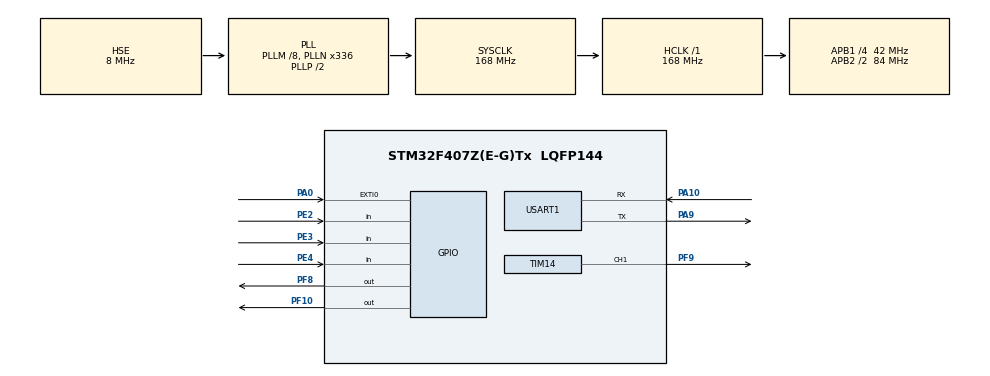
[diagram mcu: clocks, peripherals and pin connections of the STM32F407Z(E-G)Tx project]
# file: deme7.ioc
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Mcu.Family=STM32F4
Mcu.Name=STM32F407Z(E-G)Tx
Mcu.Package=LQFP144
NVIC.EXTI0_IRQn=true\:2\:3\:true\:false\:true\:true\:true
NVIC.PriorityGroup=NVIC_PRIORITYGROUP_2
NVIC.TIM3_IRQn=true\:2\:2\:true\:false\:true\:true\:true
NVIC.TIM7_IRQn=true\:1\:2\:true\:false\:true\:true\:true
NVIC.USART1_IRQn=true\:3\:3\:true\:false\:true\:true\:true
PA0-WKUP.GPIO_ModeDefaultEXTI=GPIO_MODE_IT_RISING
PA0-WKUP.GPIO_PuPd=GPIO_PULLDOWN
PA0-WKUP.Signal=GPXTI0
PA10.GPIO_Speed=GPIO_SPEED_FREQ_HIGH
PA10.Mode=Asynchronous
PA10.Signal=USART1_RX
PA9.GPIO_ModeDefaultPP=GPIO_MODE_AF_PP
PA9.Mode=Asynchronous
PA9.Signal=USART1_TX
PE2.GPIO_PuPd=GPIO_PULLUP
PE2.Signal=GPIO_Input
PE3.GPIO_PuPd=GPIO_PULLUP
PE3.Signal=GPIO_Input
PE4.GPIO_PuPd=GPIO_PULLUP
PE4.Signal=GPIO_Input
PF10.GPIO_ModeDefaultOutputPP=GPIO_MODE_OUTPUT_PP
PF10.GPIO_PuPd=GPIO_PULLUP
PF10.GPIO_Speed=GPIO_SPEED_FREQ_HIGH
PF10.PinState=GPIO_PIN_SET
PF10.Signal=GPIO_Output
PF8.GPIO_ModeDefaultOutputPP=GPIO_MODE_OUTPUT_PP
PF8.GPIO_PuPd=GPIO_PULLDOWN
PF8.GPIO_Speed=GPIO_SPEED_FREQ_HIGH
PF8.PinState=GPIO_PIN_SET
PF8.Signal=GPIO_Output
PF9.GPIO_ModeDefaultPP=GPIO_MODE_AF_PP
PF9.GPIO_PuPd=GPIO_PULLUP
PF9.GPIO_Speed=GPIO_SPEED_FREQ_HIGH
PF9.Signal=S_TIM14_CH1
PH0-OSC_IN.Mode=HSE-External-Oscillator
PH0-OSC_IN.Signal=RCC_OSC_IN
PH1-OSC_OUT.Mode=HSE-External-Oscillator
PH1-OSC_OUT.Signal=RCC_OSC_OUT
ProjectManager.HeapSize=0x200
ProjectManager.StackSize=0x400
ProjectManager.TargetToolchain=MDK-ARM V5.27
RCC.48MHZClocksFreq_Value=84000000
RCC.AHBFreq_Value=168000000
RCC.APB1CLKDivider=RCC_HCLK_DIV4
RCC.APB1Freq_Value=42000000
RCC.APB1TimFreq_Value=84000000
RCC.APB2CLKDivider=RCC_HCLK_DIV2
RCC.APB2Freq_Value=84000000
RCC.APB2TimFreq_Value=168000000
RCC.CortexFreq_Value=168000000
RCC.HCLKFreq_Value=168000000
RCC.HSE_VALUE=8000000
RCC.HSI_VALUE=16000000
RCC.LSE_VALUE=32768
RCC.PLLM=8
RCC.PLLN=336
RCC.PLLSourceVirtual=RCC_PLLSOURCE_HSE
RCC.SYSCLKFreq_VALUE=168000000
RCC.SYSCLKSource=RCC_SYSCLKSOURCE_PLLCLK
RCC.VCOOutputFreq_Value=336000000
SH.S_TIM14_CH1.0=TIM14_CH1,PWM Generation1 CH1
TIM14.AutoReloadPreload=TIM_AUTORELOAD_PRELOAD_ENABLE
TIM14.Channel=TIM_CHANNEL_1
TIM14.Period=499
TIM14.Prescaler=83
TIM3.AutoReloadPreload=TIM_AUTORELOAD_PRELOAD_ENABLE
TIM3.Period=1000
TIM3.Prescaler=8399
TIM7.AutoReloadPreload=TIM_AUTORELOAD_PRELOAD_ENABLE
TIM7.Period=1000
TIM7.Prescaler=8499
USART1.VirtualMode=VM_ASYNC
VP_TIM14_VS_ClockSourceINT.Mode=Enable_Timer
VP_TIM3_VS_ClockSourceINT.Mode=Internal
VP_TIM7_VS_ClockSourceINT.Mode=Enable_Timer
board=custom

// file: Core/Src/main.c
/* USER CODE BEGIN Header */
/**
  ******************************************************************************
  * @file           : main.c
  * @brief          : Main program body
  ******************************************************************************
  * @attention
  *
  * <h2><center>&copy; Copyright (c) 2021 STMicroelectronics.
  * All rights reserved.</center></h2>
  *
  * This software component is licensed by ST under BSD 3-Clause license,
  * the "License"; You may not use this file except in compliance with the
  * License. You may obtain a copy of the License at:
  *                        opensource.org/licenses/BSD-3-Clause
  *
  ******************************************************************************
  */
/* USER CODE END Header */
#include "main.h"
#include "tim.h"
#include "usart.h"
#include "gpio.h"

void SystemClock_Config(void);

int main(void)
{
  /* USER CODE BEGIN 1 */
	unsigned char data_buf[1];
	data_buf[0] = 0xff;
  /* USER CODE END 1 */

  /* MCU Configuration--------------------------------------------------------*/

  /* Reset of all peripherals, Initializes the Flash interface and the Systick. */
  HAL_Init();

  /* Configure the system clock */
  SystemClock_Config();

  /* Initialize all configured peripherals */
  MX_GPIO_Init();
  MX_TIM7_Init();
  MX_USART1_UART_Init();
  MX_TIM14_Init();
  MX_TIM3_Init();
  /* USER CODE BEGIN 2 */
	LED1(0);
	BEEP(0);
	Beep(0);

  /* USER CODE END 2 */

  /* Infinite loop */
  while (1)
  {

    /* USER CODE BEGIN 3 */
	  //printf("%d\n\r",0XFF);
	  if(key_state){
		  LED1(1);
	  }else{
		  LED1(0);
	  }
	  data_buf[0] = Key_Scan();
	  //HAL_UART_Transmit(&huart1, data_buf, 1, 100);
	  HAL_Delay(50);
  }
  /* USER CODE END 3 */
}

void SystemClock_Config(void)
{
  RCC_OscInitTypeDef RCC_OscInitStruct = {0};
  RCC_ClkInitTypeDef RCC_ClkInitStruct = {0};

  /** Configure the main internal regulator output voltage
  */
  __HAL_RCC_PWR_CLK_ENABLE();
  __HAL_PWR_VOLTAGESCALING_CONFIG(PWR_REGULATOR_VOLTAGE_SCALE1);
  /** Initializes the RCC Oscillators according to the specified parameters
  * in the RCC_OscInitTypeDef structure.
  */
  RCC_OscInitStruct.OscillatorType = RCC_OSCILLATORTYPE_HSE;
  RCC_OscInitStruct.HSEState = RCC_HSE_ON;
  RCC_OscInitStruct.PLL.PLLState = RCC_PLL_ON;
  RCC_OscInitStruct.PLL.PLLSource = RCC_PLLSOURCE_HSE;
  RCC_OscInitStruct.PLL.PLLM = 8;
  RCC_OscInitStruct.PLL.PLLN = 336;
  RCC_OscInitStruct.PLL.PLLP = RCC_PLLP_DIV2;
  RCC_OscInitStruct.PLL.PLLQ = 4;
  if (HAL_RCC_OscConfig(&RCC_OscInitStruct) != HAL_OK)
  {
    Error_Handler();
  }
  /** Initializes the CPU, AHB and APB buses clocks
  */
  RCC_ClkInitStruct.ClockType = RCC_CLOCKTYPE_HCLK|RCC_CLOCKTYPE_SYSCLK
                              |RCC_CLOCKTYPE_PCLK1|RCC_CLOCKTYPE_PCLK2;
  RCC_ClkInitStruct.SYSCLKSource = RCC_SYSCLKSOURCE_PLLCLK;
  RCC_ClkInitStruct.AHBCLKDivider = RCC_SYSCLK_DIV1;
  RCC_ClkInitStruct.APB1CLKDivider = RCC_HCLK_DIV4;
  RCC_ClkInitStruct.APB2CLKDivider = RCC_HCLK_DIV2;

  if (HAL_RCC_ClockConfig(&RCC_ClkInitStruct, FLASH_LATENCY_5) != HAL_OK)
  {
    Error_Handler();
  }
}

void Error_Handler(void)
{
  __disable_irq();
  while (1)
  {
  }
}

/************************ (C) COPYRIGHT STMicroelectronics *****END OF FILE****/
